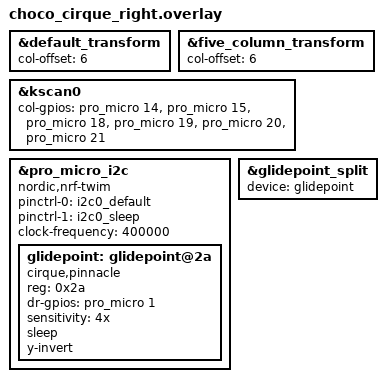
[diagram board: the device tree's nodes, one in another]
/*
 * Copyright (c) 2020 Pete Johanson
 *
 * SPDX-License-Identifier: MIT
 */

#include "choco_cirque.dtsi"

&default_transform {
    col-offset = <6>;
};

&five_column_transform {
    col-offset = <6>;
};

&kscan0 {
    col-gpios
        = <&pro_micro 14 GPIO_ACTIVE_HIGH>
        , <&pro_micro 15 GPIO_ACTIVE_HIGH>
        , <&pro_micro 18 GPIO_ACTIVE_HIGH>
        , <&pro_micro 19 GPIO_ACTIVE_HIGH>
        , <&pro_micro 20 GPIO_ACTIVE_HIGH>
        , <&pro_micro 21 GPIO_ACTIVE_HIGH>
        ;
};

&pro_micro_i2c {
    status = "okay";
    compatible = "nordic,nrf-twim";
    pinctrl-0 = <&i2c0_default>;
    pinctrl-1 = <&i2c0_sleep>;
    pinctrl-names = "default", "sleep";
    clock-frequency = <400000>; // Reduziere i2c_clock speed von 400kHz auf 100kHz für mehr Stabilität


    glidepoint: glidepoint@2a {
        compatible = "cirque,pinnacle";
        reg = <0x2a>;
        status = "okay";
        dr-gpios = <&pro_micro 1 (GPIO_PULL_DOWN | GPIO_ACTIVE_HIGH)>; // Changed to gpio 1 / Pin 0.06
        sensitivity = "4x";  // Smaller number increases sensitivity
        sleep;
        //no-taps;
        y-invert;
    };
};

// Overrides for the input-split child node
&glidepoint_split {
    device = <&glidepoint>;

    // Optional
    //input-processors = <&zip_xy_transform (INPUT_TRANSFORM_XY_SWAP | INPUT_TRANSFORM_X_INVERT | INPUT_TRANSFORM_Y_INVERT)>;
};
